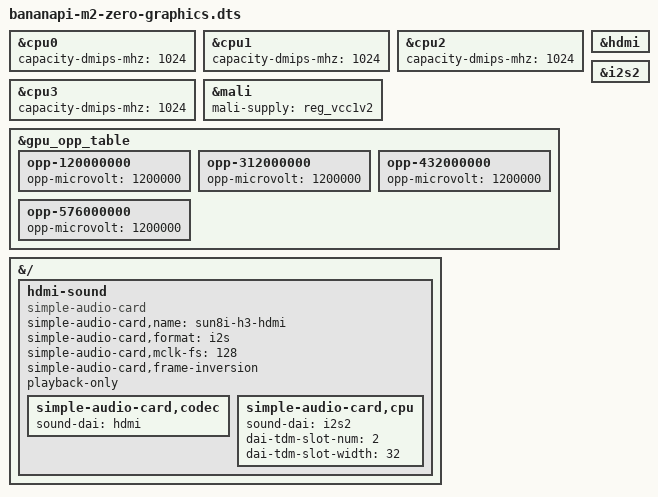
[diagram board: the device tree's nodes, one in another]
// Ajustes do device tree da Banana Pi M2 Zero usados por este projeto.
// O U-Boot aplica este overlay sobre o DTB do kernel em boot/boot.cmd.
// O DTB base precisa ter sido compilado com simbolos (DTC_FLAGS=-@).
//
// Compilacao:
//   dtc -@ -I dts -O dtb -o bananapi-m2-zero-graphics.dtbo bananapi-m2-zero-graphics.dts

/dts-v1/;
/plugin/;

// Capacidade relativa igual nos quatro Cortex-A7 (1024 nao e frequencia).
&cpu0 {
	capacity-dmips-mhz = <1024>;
};

&cpu1 {
	capacity-dmips-mhz = <1024>;
};

&cpu2 {
	capacity-dmips-mhz = <1024>;
};

&cpu3 {
	capacity-dmips-mhz = <1024>;
};

// A GPU usa a alimentacao fixa de 1,2 V em todos os pontos de operacao.
&mali {
	mali-supply = <&reg_vcc1v2>;
};

&gpu_opp_table {
	opp-120000000 {
		opp-microvolt = <1200000>;
	};

	opp-312000000 {
		opp-microvolt = <1200000>;
	};

	opp-432000000 {
		opp-microvolt = <1200000>;
	};

	opp-576000000 {
		opp-microvolt = <1200000>;
	};
};

// Audio HDMI: a I2S2 envia o audio ao controlador HDMI, e a placa de som
// simple-audio-card liga as duas pontas. O codec do HDMI exige frame clock
// invertido e slots fixos de 32 bits, configurados pelas propriedades de TDM.
&hdmi {
	#sound-dai-cells = <0>;
};

&i2s2 {
	status = "okay";
};

&{/} {
	hdmi-sound {
		compatible = "simple-audio-card";
		simple-audio-card,name = "sun8i-h3-hdmi";
		simple-audio-card,format = "i2s";
		simple-audio-card,mclk-fs = <128>;
		simple-audio-card,frame-inversion;
		// A I2S2 so tem DMA de envio (tx). Sem playback-only, a placa tambem
		// cria o fluxo de captura, nao encontra o DMA de recepcao e falha com
		// -EINVAL.
		playback-only;

		simple-audio-card,codec {
			sound-dai = <&hdmi>;
		};

		simple-audio-card,cpu {
			sound-dai = <&i2s2>;
			dai-tdm-slot-num = <2>;
			dai-tdm-slot-width = <32>;
		};
	};
};
